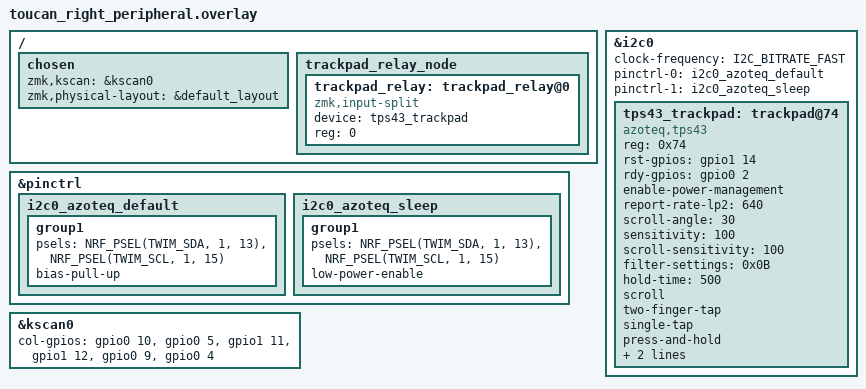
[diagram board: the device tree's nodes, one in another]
#include "toucan_common.dtsi"

/ {
    chosen {
        zmk,kscan = &kscan0;
        zmk,physical-layout = &default_layout;
    };
};

&pinctrl {
    i2c0_azoteq_default: i2c0_azoteq_default {
        group1 {
            psels = <NRF_PSEL(TWIM_SDA, 1, 13)>,
                    <NRF_PSEL(TWIM_SCL, 1, 15)>;
            bias-pull-up;
        };
    };

    i2c0_azoteq_sleep: i2c0_azoteq_sleep {
        group1 {
            psels = <NRF_PSEL(TWIM_SDA, 1, 13)>,
                    <NRF_PSEL(TWIM_SCL, 1, 15)>;
            low-power-enable;
        };
    };
};

&i2c0 {
    status = "okay";
    clock-frequency = <I2C_BITRATE_FAST>;
    pinctrl-0 = <&i2c0_azoteq_default>;
    pinctrl-1 = <&i2c0_azoteq_sleep>;
    pinctrl-names = "default", "sleep";

    tps43_trackpad: trackpad@74 {
        compatible = "azoteq,tps43";
        reg = <0x74>;
        status = "okay";

        rst-gpios = <&gpio1 14 GPIO_ACTIVE_HIGH>;
        rdy-gpios = <&gpio0 2 GPIO_ACTIVE_HIGH>;

        enable-power-management;
        report-rate-lp2 = <640>;
        scroll-angle = <30>;
        sensitivity = <100>;
        scroll-sensitivity = <100>;

        filter-settings = <0x0B>;
        hold-time = <500>;

        // zoom;
        scroll;
        two-finger-tap;
        single-tap;
        press-and-hold;
        // three-finger-swipe;
        // three-finger-swipe-throttle-ms = <1200>;
        switch-xy;
        invert-scroll-y;
    };
};

/ {
    trackpad_relay_node {
        #address-cells = <1>;
        #size-cells = <0>;

        trackpad_relay: trackpad_relay@0 {
            compatible = "zmk,input-split";
            device = <&tps43_trackpad>;
            reg = <0>;
        };
    };
};

&kscan0 {
    col-gpios
    = <&gpio0 10 GPIO_ACTIVE_HIGH>
    , <&gpio0 5 GPIO_ACTIVE_HIGH>
    , <&gpio1 11 GPIO_ACTIVE_HIGH>
    , <&gpio1 12 GPIO_ACTIVE_HIGH>
    , <&gpio0 9 GPIO_ACTIVE_HIGH>
    , <&gpio0 4 GPIO_ACTIVE_HIGH>
    ;
};
